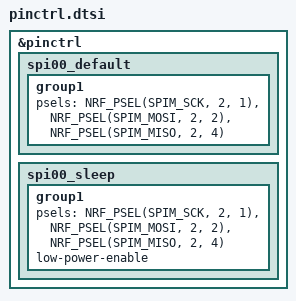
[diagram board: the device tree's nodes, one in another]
/*
 * BLEhound board definition, derived from the Zephyr nRF54LM20 DK board
 * (boards/nordic/nrf54lm20dk, Copyright (c) 2025 Nordic Semiconductor ASA).
 *
 * SPDX-License-Identifier: Apache-2.0
 */

/*
 * Inter-chip SPIM00 (downstream master port) pins.
 * V2 (revised board): the datasheet's dedicated SPIM00 pins P2.01=SCK (the only clock pin on P2), P2.02=SDO,
 * P2.04=SDI, P2.05=CSN. WARNING a V1 flywire board must not run this image: its P2.01 is the shared SYNC net, so three
 * chips driving SCK at once would fight each other.
 */
&pinctrl {
	spi00_default: spi00_default {
		group1 {
			psels = <NRF_PSEL(SPIM_SCK, 2, 1)>,
				<NRF_PSEL(SPIM_MOSI, 2, 2)>,
				<NRF_PSEL(SPIM_MISO, 2, 4)>;
		};
	};

	spi00_sleep: spi00_sleep {
		group1 {
			psels = <NRF_PSEL(SPIM_SCK, 2, 1)>,
				<NRF_PSEL(SPIM_MOSI, 2, 2)>,
				<NRF_PSEL(SPIM_MISO, 2, 4)>;
			low-power-enable;
		};
	};
};
